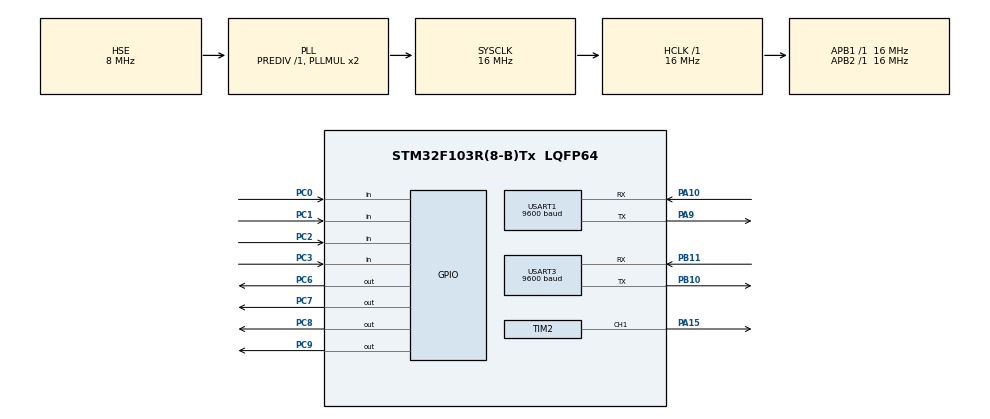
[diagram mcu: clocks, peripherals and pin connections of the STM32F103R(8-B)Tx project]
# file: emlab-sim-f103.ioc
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Dma.Request0=USART3_RX
Dma.Request1=USART3_TX
Dma.USART3_RX.0.Direction=DMA_PERIPH_TO_MEMORY
Dma.USART3_RX.0.Instance=DMA1_Channel3
Dma.USART3_RX.0.MemDataAlignment=DMA_MDATAALIGN_BYTE
Dma.USART3_RX.0.MemInc=DMA_MINC_ENABLE
Dma.USART3_RX.0.Mode=DMA_NORMAL
Dma.USART3_RX.0.PeriphDataAlignment=DMA_PDATAALIGN_BYTE
Dma.USART3_RX.0.PeriphInc=DMA_PINC_DISABLE
Dma.USART3_RX.0.Priority=DMA_PRIORITY_LOW
Dma.USART3_TX.1.Direction=DMA_MEMORY_TO_PERIPH
Dma.USART3_TX.1.Instance=DMA1_Channel2
Dma.USART3_TX.1.MemDataAlignment=DMA_MDATAALIGN_BYTE
Dma.USART3_TX.1.MemInc=DMA_MINC_ENABLE
Dma.USART3_TX.1.Mode=DMA_NORMAL
Dma.USART3_TX.1.PeriphDataAlignment=DMA_PDATAALIGN_BYTE
Dma.USART3_TX.1.PeriphInc=DMA_PINC_DISABLE
Dma.USART3_TX.1.Priority=DMA_PRIORITY_LOW
Mcu.Family=STM32F1
Mcu.Name=STM32F103R(8-B)Tx
Mcu.Package=LQFP64
NVIC.DMA1_Channel2_IRQn=true\:0\:0\:false\:false\:true\:false\:true\:true
NVIC.DMA1_Channel3_IRQn=true\:0\:0\:false\:false\:true\:false\:true\:true
NVIC.PriorityGroup=NVIC_PRIORITYGROUP_4
NVIC.USART3_IRQn=true\:0\:0\:false\:false\:true\:true\:true\:true
PA10.Mode=Asynchronous
PA10.Signal=USART1_RX
PA15.Signal=S_TIM2_CH1_ETR
PA9.Mode=Asynchronous
PA9.Signal=USART1_TX
PB10.Mode=Asynchronous
PB10.Signal=USART3_TX
PB11.Mode=Asynchronous
PB11.Signal=USART3_RX
PC0.GPIO_PuPd=GPIO_PULLUP
PC0.Signal=GPIO_Input
PC1.GPIO_PuPd=GPIO_PULLUP
PC1.Signal=GPIO_Input
PC2.GPIO_PuPd=GPIO_PULLUP
PC2.Signal=GPIO_Input
PC3.GPIO_PuPd=GPIO_PULLUP
PC3.Signal=GPIO_Input
PC6.Signal=GPIO_Output
PC7.Signal=GPIO_Output
PC8.Signal=GPIO_Output
PC9.Signal=GPIO_Output
PD0-OSC_IN.Mode=HSE-External-Oscillator
PD0-OSC_IN.Signal=RCC_OSC_IN
PD1-OSC_OUT.Mode=HSE-External-Oscillator
PD1-OSC_OUT.Signal=RCC_OSC_OUT
ProjectManager.HeapSize=0x200
ProjectManager.StackSize=0x400
ProjectManager.TargetToolchain=MDK-ARM V5
RCC.AHBFreq_Value=16000000
RCC.APB1Freq_Value=16000000
RCC.APB1TimFreq_Value=16000000
RCC.APB2Freq_Value=16000000
RCC.APB2TimFreq_Value=16000000
RCC.HCLKFreq_Value=16000000
RCC.PLLSourceVirtual=RCC_PLLSOURCE_HSE
RCC.SYSCLKFreq_VALUE=16000000
RCC.SYSCLKSource=RCC_SYSCLKSOURCE_PLLCLK
RCC.USBFreq_Value=16000000
SH.S_TIM2_CH1_ETR.0=TIM2_CH1,PWM Generation1 CH1
TIM2.Channel-PWM\ Generation1\ CH1=TIM_CHANNEL_1
TIM2.Prescaler=15
USART1.BaudRate=9600
USART1.VirtualMode=VM_ASYNC
USART3.BaudRate=9600
USART3.VirtualMode=VM_ASYNC
VP_SYS_VS_ND.Mode=No_Debug
board=custom

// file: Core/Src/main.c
/* USER CODE BEGIN Header */
/**
  ******************************************************************************
  * @file           : main.c
  * @brief          : Main program body
  ******************************************************************************
  * @attention
  *
  * Copyright (c) 2022 STMicroelectronics.
  * All rights reserved.
  *
  * This software is licensed under terms that can be found in the LICENSE file
  * in the root directory of this software component.
  * If no LICENSE file comes with this software, it is provided AS-IS.
  *
  ******************************************************************************
  */
/* USER CODE END Header */
#include "main.h"

TIM_HandleTypeDef htim2;

UART_HandleTypeDef huart1;
UART_HandleTypeDef huart3;
DMA_HandleTypeDef hdma_usart3_rx;
DMA_HandleTypeDef hdma_usart3_tx;

void SystemClock_Config(void);
static void MX_GPIO_Init(void);
static void MX_DMA_Init(void);
static void MX_USART1_UART_Init(void);
static void MX_USART3_UART_Init(void);
static void MX_TIM2_Init(void);

/* USER CODE BEGIN 0 */
void kern_init(void);
void app_main(void);
void kern_start(void);

/* USER CODE END 0 */

int main(void)
{

  /* MCU Configuration--------------------------------------------------------*/

  /* Reset of all peripherals, Initializes the Flash interface and the Systick. */
  HAL_Init();

  /* Configure the system clock */
  SystemClock_Config();

  /* Initialize all configured peripherals */
  MX_GPIO_Init();
  MX_DMA_Init();
  MX_USART1_UART_Init();
  MX_USART3_UART_Init();
  MX_TIM2_Init();
  /* USER CODE BEGIN 2 */
	kern_init();	//初始化内核
	app_main();	//应用程序入口
	kern_start();	//启动内核调度

  /* USER CODE END 2 */

  /* Infinite loop */
  while (1)
  {

  }
}

void SystemClock_Config(void)
{
  RCC_OscInitTypeDef RCC_OscInitStruct = {0};
  RCC_ClkInitTypeDef RCC_ClkInitStruct = {0};

  /** Initializes the RCC Oscillators according to the specified parameters
  * in the RCC_OscInitTypeDef structure.
  */
  RCC_OscInitStruct.OscillatorType = RCC_OSCILLATORTYPE_HSE;
  RCC_OscInitStruct.HSEState = RCC_HSE_ON;
  RCC_OscInitStruct.HSEPredivValue = RCC_HSE_PREDIV_DIV1;
  RCC_OscInitStruct.HSIState = RCC_HSI_ON;
  RCC_OscInitStruct.PLL.PLLState = RCC_PLL_ON;
  RCC_OscInitStruct.PLL.PLLSource = RCC_PLLSOURCE_HSE;
  RCC_OscInitStruct.PLL.PLLMUL = RCC_PLL_MUL2;
  if (HAL_RCC_OscConfig(&RCC_OscInitStruct) != HAL_OK)
  {
    Error_Handler();
  }

  /** Initializes the CPU, AHB and APB buses clocks
  */
  RCC_ClkInitStruct.ClockType = RCC_CLOCKTYPE_HCLK|RCC_CLOCKTYPE_SYSCLK
                              |RCC_CLOCKTYPE_PCLK1|RCC_CLOCKTYPE_PCLK2;
  RCC_ClkInitStruct.SYSCLKSource = RCC_SYSCLKSOURCE_PLLCLK;
  RCC_ClkInitStruct.AHBCLKDivider = RCC_SYSCLK_DIV1;
  RCC_ClkInitStruct.APB1CLKDivider = RCC_HCLK_DIV1;
  RCC_ClkInitStruct.APB2CLKDivider = RCC_HCLK_DIV1;

  if (HAL_RCC_ClockConfig(&RCC_ClkInitStruct, FLASH_LATENCY_0) != HAL_OK)
  {
    Error_Handler();
  }
}

static void MX_TIM2_Init(void)
{

  TIM_MasterConfigTypeDef sMasterConfig = {0};
  TIM_OC_InitTypeDef sConfigOC = {0};

  htim2.Instance = TIM2;
  htim2.Init.Prescaler = 15;
  htim2.Init.CounterMode = TIM_COUNTERMODE_UP;
  htim2.Init.Period = 65535;
  htim2.Init.ClockDivision = TIM_CLOCKDIVISION_DIV1;
  htim2.Init.AutoReloadPreload = TIM_AUTORELOAD_PRELOAD_DISABLE;
  if (HAL_TIM_PWM_Init(&htim2) != HAL_OK)
  {
    Error_Handler();
  }
  sMasterConfig.MasterOutputTrigger = TIM_TRGO_RESET;
  sMasterConfig.MasterSlaveMode = TIM_MASTERSLAVEMODE_DISABLE;
  if (HAL_TIMEx_MasterConfigSynchronization(&htim2, &sMasterConfig) != HAL_OK)
  {
    Error_Handler();
  }
  sConfigOC.OCMode = TIM_OCMODE_PWM1;
  sConfigOC.Pulse = 0;
  sConfigOC.OCPolarity = TIM_OCPOLARITY_HIGH;
  sConfigOC.OCFastMode = TIM_OCFAST_DISABLE;
  if (HAL_TIM_PWM_ConfigChannel(&htim2, &sConfigOC, TIM_CHANNEL_1) != HAL_OK)
  {
    Error_Handler();
  }
  HAL_TIM_MspPostInit(&htim2);

}

static void MX_USART1_UART_Init(void)
{

  huart1.Instance = USART1;
  huart1.Init.BaudRate = 9600;
  huart1.Init.WordLength = UART_WORDLENGTH_8B;
  huart1.Init.StopBits = UART_STOPBITS_1;
  huart1.Init.Parity = UART_PARITY_NONE;
  huart1.Init.Mode = UART_MODE_TX_RX;
  huart1.Init.HwFlowCtl = UART_HWCONTROL_NONE;
  huart1.Init.OverSampling = UART_OVERSAMPLING_16;
  if (HAL_UART_Init(&huart1) != HAL_OK)
  {
    Error_Handler();
  }

}

static void MX_USART3_UART_Init(void)
{

  huart3.Instance = USART3;
  huart3.Init.BaudRate = 9600;
  huart3.Init.WordLength = UART_WORDLENGTH_8B;
  huart3.Init.StopBits = UART_STOPBITS_1;
  huart3.Init.Parity = UART_PARITY_NONE;
  huart3.Init.Mode = UART_MODE_TX_RX;
  huart3.Init.HwFlowCtl = UART_HWCONTROL_NONE;
  huart3.Init.OverSampling = UART_OVERSAMPLING_16;
  if (HAL_UART_Init(&huart3) != HAL_OK)
  {
    Error_Handler();
  }

}

static void MX_DMA_Init(void)
{

  /* DMA controller clock enable */
  __HAL_RCC_DMA1_CLK_ENABLE();

  /* DMA interrupt init */
  /* DMA1_Channel2_IRQn interrupt configuration */
  HAL_NVIC_SetPriority(DMA1_Channel2_IRQn, 0, 0);
  HAL_NVIC_EnableIRQ(DMA1_Channel2_IRQn);
  /* DMA1_Channel3_IRQn interrupt configuration */
  HAL_NVIC_SetPriority(DMA1_Channel3_IRQn, 0, 0);
  HAL_NVIC_EnableIRQ(DMA1_Channel3_IRQn);

}

static void MX_GPIO_Init(void)
{
  GPIO_InitTypeDef GPIO_InitStruct = {0};

  /* GPIO Ports Clock Enable */
  __HAL_RCC_GPIOD_CLK_ENABLE();
  __HAL_RCC_GPIOC_CLK_ENABLE();
  __HAL_RCC_GPIOB_CLK_ENABLE();
  __HAL_RCC_GPIOA_CLK_ENABLE();

  /*Configure GPIO pin Output Level */
  HAL_GPIO_WritePin(GPIOC, GPIO_PIN_6|GPIO_PIN_7|GPIO_PIN_8|GPIO_PIN_9, GPIO_PIN_RESET);

  /*Configure GPIO pins : PC0 PC1 PC2 PC3 */
  GPIO_InitStruct.Pin = GPIO_PIN_0|GPIO_PIN_1|GPIO_PIN_2|GPIO_PIN_3;
  GPIO_InitStruct.Mode = GPIO_MODE_INPUT;
  GPIO_InitStruct.Pull = GPIO_PULLUP;
  HAL_GPIO_Init(GPIOC, &GPIO_InitStruct);

  /*Configure GPIO pins : PC6 PC7 PC8 PC9 */
  GPIO_InitStruct.Pin = GPIO_PIN_6|GPIO_PIN_7|GPIO_PIN_8|GPIO_PIN_9;
  GPIO_InitStruct.Mode = GPIO_MODE_OUTPUT_PP;
  GPIO_InitStruct.Pull = GPIO_NOPULL;
  GPIO_InitStruct.Speed = GPIO_SPEED_FREQ_LOW;
  HAL_GPIO_Init(GPIOC, &GPIO_InitStruct);

}

void Error_Handler(void)
{
  __disable_irq();
  while (1)
  {
  }
}
